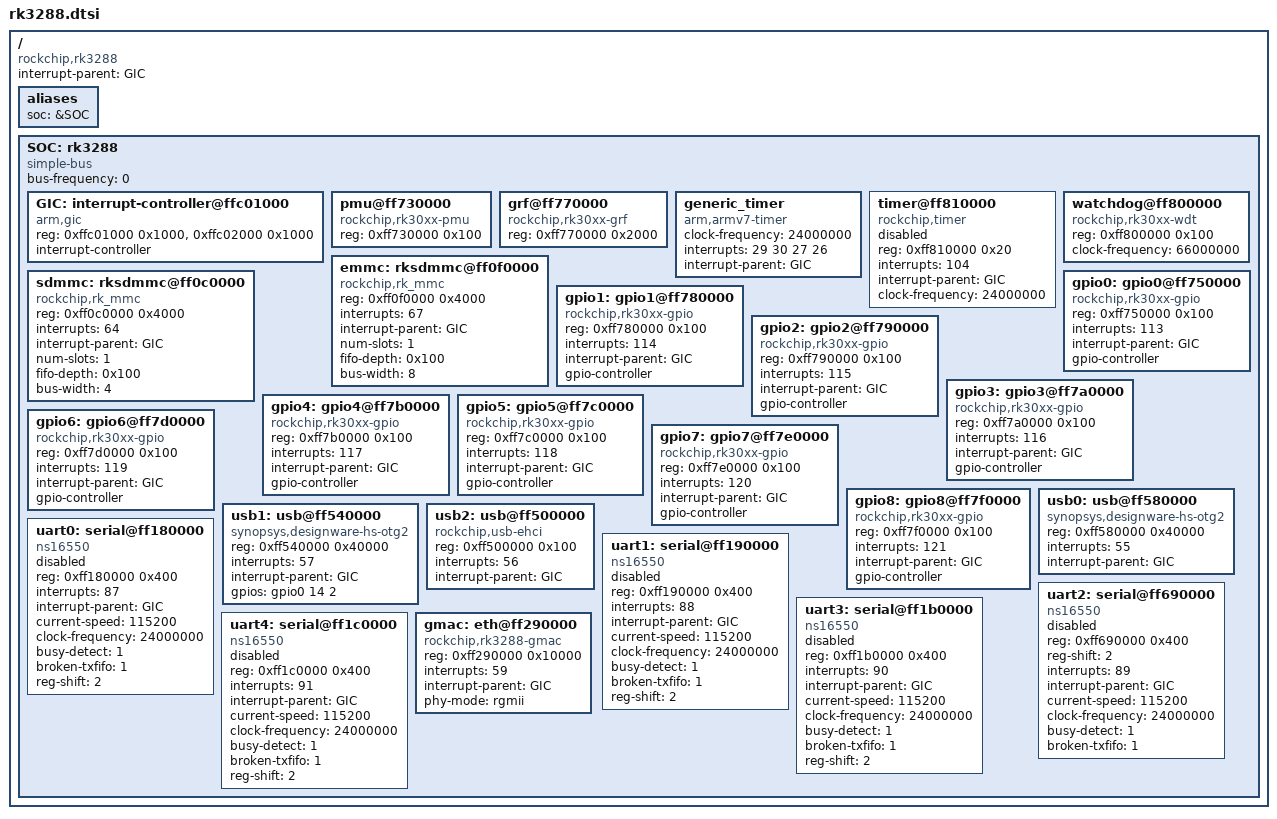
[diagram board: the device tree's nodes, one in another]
/*-
 * Copyright (c) 2015 Ganbold Tsagaankhuu <ganbold@freebsd.org>
 * All rights reserved.
 *
 * Redistribution and use in source and binary forms, with or without
 * modification, are permitted provided that the following conditions
 * are met:
 * 1. Redistributions of source code must retain the above copyright
 *    notice, this list of conditions and the following disclaimer.
 * 2. Redistributions in binary form must reproduce the above copyright
 *    notice, this list of conditions and the following disclaimer in the
 *    documentation and/or other materials provided with the distribution.
 *
 * THIS SOFTWARE IS PROVIDED BY THE AUTHOR AND CONTRIBUTORS ``AS IS'' AND
 * ANY EXPRESS OR IMPLIED WARRANTIES, INCLUDING, BUT NOT LIMITED TO, THE
 * IMPLIED WARRANTIES OF MERCHANTABILITY AND FITNESS FOR A PARTICULAR PURPOSE
 * ARE DISCLAIMED.  IN NO EVENT SHALL THE AUTHOR OR CONTRIBUTORS BE LIABLE
 * FOR ANY DIRECT, INDIRECT, INCIDENTAL, SPECIAL, EXEMPLARY, OR CONSEQUENTIAL
 * DAMAGES (INCLUDING, BUT NOT LIMITED TO, PROCUREMENT OF SUBSTITUTE GOODS
 * OR SERVICES; LOSS OF USE, DATA, OR PROFITS; OR BUSINESS INTERRUPTION)
 * HOWEVER CAUSED AND ON ANY THEORY OF LIABILITY, WHETHER IN CONTRACT, STRICT
 * LIABILITY, OR TORT (INCLUDING NEGLIGENCE OR OTHERWISE) ARISING IN ANY WAY
 * OUT OF THE USE OF THIS SOFTWARE, EVEN IF ADVISED OF THE POSSIBILITY OF
 * SUCH DAMAGE.
 *
 * $FreeBSD$
 */

/ {
	compatible = "rockchip,rk3288";
	#address-cells = <1>;
	#size-cells = <1>;

	interrupt-parent = <&GIC>;

	aliases {
		soc = &SOC;
	};

	SOC: rk3288 {
		#address-cells = <1>;
		#size-cells = <1>;
		compatible = "simple-bus";
		ranges;
		bus-frequency = <0>;

		GIC: interrupt-controller@ffc01000 {
			compatible = "arm,gic";
			reg =	<0xffc01000 0x1000>,	/* Distributor Registers */
				<0xffc02000 0x1000>;	/* CPU Interface Registers */
			interrupt-controller;
			#interrupt-cells = <1>;
		};

		pmu@ff730000 {
			compatible = "rockchip,rk30xx-pmu";
			#address-cells = <1>;
			#size-cells = <1>;
			reg = <0xff730000 0x100>;
		};

		grf@ff770000 {
			compatible = "rockchip,rk30xx-grf";
			#address-cells = <1>;
			#size-cells = <1>;
			reg = < 0xff770000 0x2000 >;
		};

		generic_timer {
			compatible = "arm,armv7-timer";
			clock-frequency = <24000000>;
			interrupts = < 29 30 27 26 >;
			interrupt-parent = <&GIC>;
		};

		timer@ff810000 {
			compatible = "rockchip,timer";
			reg = <0xff810000 0x20>;
			interrupts = <104>;
			interrupt-parent = <&GIC>;
			clock-frequency = <24000000>;
			status = "disabled";
		};

		watchdog@ff800000 {
			compatible = "rockchip,rk30xx-wdt";
			reg = <0xff800000 0x100>;
			clock-frequency = < 66000000 >;	/* TODO: verify freq */
		};


		emmc: rksdmmc@ff0f0000 {
			compatible = "rockchip,rk_mmc", "rockchip,rk32xx-sdmmc";
			reg = <0xff0f0000 0x4000>;
			interrupts = <67>;
			interrupt-parent = <&GIC>;
			#address-cells = <1>;
			#size-cells = <0>;
			num-slots = <1>;
			fifo-depth = <0x100>;
			bus-width = <8>;
		};

		sdmmc: rksdmmc@ff0c0000 {
			compatible = "rockchip,rk_mmc", "rockchip,rk32xx-sdmmc";
			reg = <0xff0c0000 0x4000>;
			interrupts = <64>;
			interrupt-parent = <&GIC>;
			#address-cells = <1>;
			#size-cells = <0>;
			num-slots = <1>;
			fifo-depth = <0x100>;
			bus-width = <4>;
		};

		gpio0: gpio0@ff750000 {
			compatible = "rockchip,rk30xx-gpio";
			reg =	<0xff750000 0x100>;
			interrupts = <113>;
			interrupt-parent = <&GIC>;

			gpio-controller;
			#gpio-cells = <2>;
		};

		gpio1: gpio1@ff780000 {
			compatible = "rockchip,rk30xx-gpio";
			reg = <0xff780000 0x100>;
			interrupts = <114>;
			interrupt-parent = <&GIC>;

			gpio-controller;
			#gpio-cells = <2>;
		};

		gpio2: gpio2@ff790000 {
			compatible = "rockchip,rk30xx-gpio";
			reg = <0xff790000 0x100>;
			interrupts = <115>;
			interrupt-parent = <&GIC>;

			gpio-controller;
			#gpio-cells = <2>;
		};

		gpio3: gpio3@ff7a0000 {
			compatible = "rockchip,rk30xx-gpio";
			reg = <0xff7a0000 0x100>;
			interrupts = <116>;
			interrupt-parent = <&GIC>;

			gpio-controller;
			#gpio-cells = <2>;
		};

		gpio4: gpio4@ff7b0000 {
			compatible = "rockchip,rk30xx-gpio";
			reg = <0xff7b0000 0x100>;
			interrupts = <117>;
			interrupt-parent = <&GIC>;

			gpio-controller;
			#gpio-cells = <2>;
		};

		gpio5: gpio5@ff7c0000 {
			compatible = "rockchip,rk30xx-gpio";
			reg = <0xff7c0000 0x100>;
			interrupts = <118>;
			interrupt-parent = <&GIC>;

			gpio-controller;
			#gpio-cells = <2>;
		};

		gpio6: gpio6@ff7d0000 {
			compatible = "rockchip,rk30xx-gpio";
			reg = <0xff7d0000 0x100>;
			interrupts = <119>;
			interrupt-parent = <&GIC>;

			gpio-controller;
			#gpio-cells = <2>;
		};

		gpio7: gpio7@ff7e0000 {
			compatible = "rockchip,rk30xx-gpio";
			reg = <0xff7e0000 0x100>;
			interrupts = <120>;
			interrupt-parent = <&GIC>;

			gpio-controller;
			#gpio-cells = <2>;
		};

		gpio8: gpio8@ff7f0000 {
			compatible = "rockchip,rk30xx-gpio";
			reg = <0xff7f0000 0x100>;
			interrupts = <121>;
			interrupt-parent = <&GIC>;

			gpio-controller;
			#gpio-cells = <2>;
		};

		usb0: usb@ff580000 {
			compatible = "synopsys,designware-hs-otg2";
			reg = <0xff580000 0x40000>;
			interrupts = <55>;
			interrupt-parent = <&GIC>;
			#address-cells = <1>;
			#size-cells = <0>;
		};

		usb1: usb@ff540000 {
			compatible = "synopsys,designware-hs-otg2";
			reg = <0xff540000 0x40000>;
			interrupts = <57>;
			interrupt-parent = <&GIC>;
			#address-cells = <1>;
			#size-cells = <0>;
			gpios = <&gpio0 14 2 2>;
		};

		usb2: usb@ff500000 {
			compatible = "rockchip,usb-ehci", "usb-ehci";
			reg = <0xff500000 0x100>;
			interrupts = <56>;
			interrupt-parent = <&GIC>;
			#address-cells = <1>;
			#size-cells = <0>;
		};

		uart0: serial@ff180000 {
			compatible = "ns16550";
			reg = <0xff180000 0x400>;
			interrupts = <87>;
			interrupt-parent = <&GIC>;
			current-speed = <115200>;
			clock-frequency = < 24000000 >;
			busy-detect = <1>;
			broken-txfifo = <1>;
			reg-shift = <2>;
			status = "disabled";
		};

		uart1: serial@ff190000 {
			compatible = "ns16550";
			reg = <0xff190000 0x400>;
			interrupts = <88>;
			interrupt-parent = <&GIC>;
			current-speed = <115200>;
			clock-frequency = < 24000000 >;
			busy-detect = <1>;
			broken-txfifo = <1>;
			reg-shift = <2>;
			status = "disabled";
		};

		uart2: serial@ff690000 {
			compatible = "ns16550";
			reg = <0xff690000 0x400>;
			reg-shift = <2>;
			interrupts = <89>;
			interrupt-parent = <&GIC>;
			current-speed = <115200>;
			clock-frequency = < 24000000 >;
			busy-detect = <1>;
			broken-txfifo = <1>;
			status = "disabled";
		};

		uart3: serial@ff1b0000 {
			compatible = "ns16550";
			reg = <0xff1b0000 0x400>;
			interrupts = <90>;
			interrupt-parent = <&GIC>;
			current-speed = <115200>;
			clock-frequency = < 24000000 >;
			busy-detect = <1>;
			broken-txfifo = <1>;
			reg-shift = <2>;
			status = "disabled";
		};

		uart4: serial@ff1c0000 {
			compatible = "ns16550";
			reg = <0xff1c0000 0x400>;
			interrupts = <91>;
			interrupt-parent = <&GIC>;
			current-speed = <115200>;
			clock-frequency = < 24000000 >;
			busy-detect = <1>;
			broken-txfifo = <1>;
			reg-shift = <2>;
			status = "disabled";
		};

		gmac: eth@ff290000 {
			compatible = "rockchip,rk3288-gmac";
			reg = <0xff290000 0x10000>;
			interrupts = <59>;
			interrupt-parent = <&GIC>;
			interrupt-names = "macirq";
			//phy-mode = "rmii";
			phy-mode = "rgmii";
		};
	};
};

